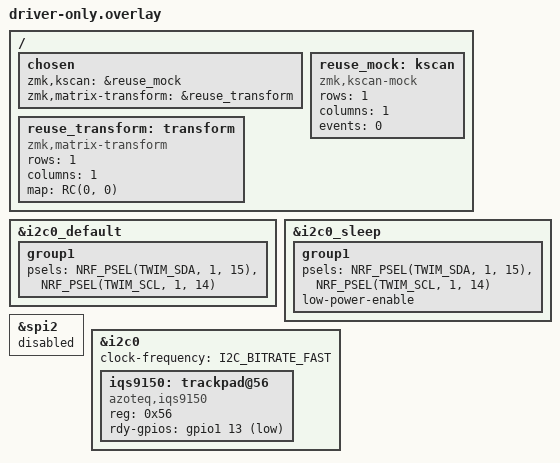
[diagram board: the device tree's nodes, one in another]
/* XIAO build fixture, not reusable pin assignments.
 * XIAO向けビルド確認例。実際のキーボードでは配線を置き換える。 */
#include <zephyr/dt-bindings/pinctrl/nrf-pinctrl.h>
#include <dt-bindings/zmk/matrix_transform.h>

&i2c0_default {
    group1 { psels = <NRF_PSEL(TWIM_SDA, 1, 15)>, <NRF_PSEL(TWIM_SCL, 1, 14)>; };
};
&i2c0_sleep {
    group1 {
        psels = <NRF_PSEL(TWIM_SDA, 1, 15)>, <NRF_PSEL(TWIM_SCL, 1, 14)>;
        low-power-enable;
    };
};
&spi2 { status = "disabled"; };
&i2c0 {
    status = "okay";
    clock-frequency = <I2C_BITRATE_FAST>;
    iqs9150: trackpad@56 {
        compatible = "azoteq,iqs9150";
        reg = <0x56>;
        rdy-gpios = <&gpio1 13 GPIO_ACTIVE_LOW>;
    };
};

/* Stand-in for the consuming keyboard's own KSCAN and transform.
 * 接続先キーボード所有のKSCAN・transformの代わりとなるビルド用mock。 */
/ {
    chosen {
        zmk,kscan = &reuse_mock;
        zmk,matrix-transform = &reuse_transform;
    };
    reuse_mock: kscan {
        compatible = "zmk,kscan-mock";
        rows = <1>;
        columns = <1>;
        events = <0>;
    };
    reuse_transform: transform {
        compatible = "zmk,matrix-transform";
        rows = <1>;
        columns = <1>;
        map = <RC(0, 0)>;
    };
};
